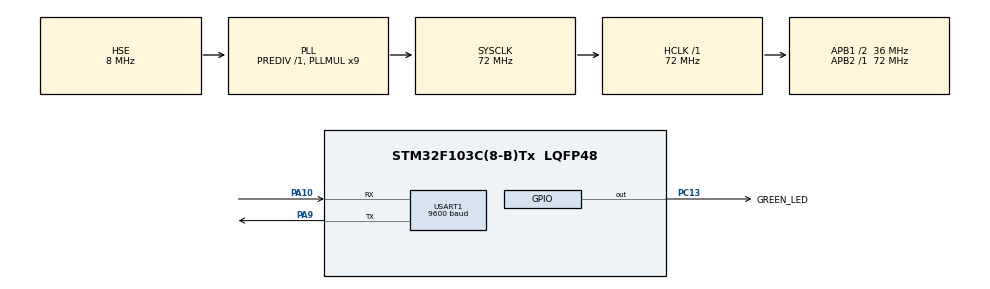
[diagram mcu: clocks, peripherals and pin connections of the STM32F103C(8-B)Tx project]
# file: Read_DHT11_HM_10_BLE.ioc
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Mcu.Family=STM32F1
Mcu.Name=STM32F103C(8-B)Tx
Mcu.Package=LQFP48
NVIC.PriorityGroup=NVIC_PRIORITYGROUP_4
NVIC.USART1_IRQn=true\:0\:0\:false\:false\:true\:true\:true
PA10.Mode=Asynchronous
PA10.Signal=USART1_RX
PA13.Mode=Serial_Wire
PA13.Signal=SYS_JTMS-SWDIO
PA14.Mode=Serial_Wire
PA14.Signal=SYS_JTCK-SWCLK
PA9.Mode=Asynchronous
PA9.Signal=USART1_TX
PC13-TAMPER-RTC.GPIO_Label=GREEN_LED
PC13-TAMPER-RTC.Signal=GPIO_Output
PD0-OSC_IN.Mode=HSE-External-Oscillator
PD0-OSC_IN.Signal=RCC_OSC_IN
PD1-OSC_OUT.Mode=HSE-External-Oscillator
PD1-OSC_OUT.Signal=RCC_OSC_OUT
ProjectManager.HeapSize=0x200
ProjectManager.StackSize=0x400
ProjectManager.TargetToolchain=STM32CubeIDE
RCC.AHBFreq_Value=72000000
RCC.APB1CLKDivider=RCC_HCLK_DIV2
RCC.APB1Freq_Value=36000000
RCC.APB1TimFreq_Value=72000000
RCC.APB2Freq_Value=72000000
RCC.APB2TimFreq_Value=72000000
RCC.HCLKFreq_Value=72000000
RCC.PLLMUL=RCC_PLL_MUL9
RCC.PLLSourceVirtual=RCC_PLLSOURCE_HSE
RCC.SYSCLKFreq_VALUE=72000000
RCC.SYSCLKSource=RCC_SYSCLKSOURCE_PLLCLK
RCC.USBFreq_Value=72000000
TIM1.Prescaler=71
USART1.BaudRate=9600
USART1.VirtualMode=VM_ASYNC
VP_TIM1_VS_ClockSourceINT.Mode=Internal
board=custom

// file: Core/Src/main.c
/* USER CODE BEGIN Header */
/**
  ******************************************************************************
  * @file           : main.c
  * @brief          : Main program body
  ******************************************************************************
  * @attention
  *
  * <h2><center>&copy; Copyright (c) 2025 STMicroelectronics.
  * All rights reserved.</center></h2>
  *
  * This software component is licensed by ST under BSD 3-Clause license,
  * the "License"; You may not use this file except in compliance with the
  * License. You may obtain a copy of the License at:
  *                        opensource.org/licenses/BSD-3-Clause
  *
  ******************************************************************************
  */
/* USER CODE END Header */
#include "main.h"

/* USER CODE BEGIN Includes */
#include "stdio.h"
#include "string.h"
/* USER CODE END Includes */

/* USER CODE BEGIN PD */
#define DHT11_PORT GPIOA
#define DHT11_PIN GPIO_PIN_0

#define HM10_UART &huart1  // Define the UART used for HM-10
/* USER CODE END PD */

TIM_HandleTypeDef htim1;

UART_HandleTypeDef huart1;

/* USER CODE BEGIN PV */
uint8_t dht11_data[5];
char uart_buffer[127];
/* USER CODE END PV */

void SystemClock_Config(void);
static void MX_GPIO_Init(void);
static void MX_USART1_UART_Init(void);
static void MX_TIM1_Init(void);

/* USER CODE BEGIN 0 */

void microDelay (uint16_t delay)
{
  __HAL_TIM_SET_COUNTER(&htim1, 0);
  while (__HAL_TIM_GET_COUNTER(&htim1) < delay);
}

/* Function to initialize communication with DHT11 */
void DHT11_Start(void)
{
  GPIO_InitTypeDef GPIO_InitStruct = {0};

  /* Configure pin as output */
  GPIO_InitStruct.Pin = DHT11_PIN;
  GPIO_InitStruct.Mode = GPIO_MODE_OUTPUT_PP;
  GPIO_InitStruct.Pull = GPIO_NOPULL;
  GPIO_InitStruct.Speed = GPIO_SPEED_FREQ_LOW;
  HAL_GPIO_Init(DHT11_PORT, &GPIO_InitStruct);

  HAL_GPIO_WritePin(DHT11_PORT, DHT11_PIN, GPIO_PIN_RESET);
  HAL_Delay(20); // Pull low for >18ms
  HAL_GPIO_WritePin(DHT11_PORT, DHT11_PIN, GPIO_PIN_SET);
  microDelay(30); // Pull high for 30us

  /* Configure pin as input */
  GPIO_InitStruct.Mode = GPIO_MODE_INPUT;
  GPIO_InitStruct.Pull = GPIO_NOPULL;
  HAL_GPIO_Init(DHT11_PORT, &GPIO_InitStruct);
}

uint8_t DHT11_Check_Response(void)
{
  uint8_t response = 0;
  microDelay(40);

  if (!HAL_GPIO_ReadPin(DHT11_PORT, DHT11_PIN))
  {
	  microDelay(80);
    if (HAL_GPIO_ReadPin(DHT11_PORT, DHT11_PIN))
      response = 1;
  }
  while (HAL_GPIO_ReadPin(DHT11_PORT, DHT11_PIN)); // wait for the pin to go low

  return response;
}

uint8_t DHT11_Read(void)
{
  uint8_t i, j;
  for (j = 0; j < 8; j++)
  {
    while (!HAL_GPIO_ReadPin(DHT11_PORT, DHT11_PIN)); // Wait for pin to go high
    microDelay(40); // 40us delay
    if (!HAL_GPIO_ReadPin(DHT11_PORT, DHT11_PIN))
    {
      i &= ~(1 << (7 - j)); // Write 0
    }
    else
    {
      i |= (1 << (7 - j)); // Write 1
    }
    while (HAL_GPIO_ReadPin(DHT11_PORT, DHT11_PIN)); // Wait for pin to go low
  }
  return i;
}

void HM10_SendCommand(const char *command) {
    HAL_UART_Transmit(HM10_UART, (uint8_t *)command, strlen(command), HAL_MAX_DELAY);
    HAL_UART_Transmit(HM10_UART, (uint8_t *)"\r\n", 2, HAL_MAX_DELAY);
}

void HM10_Init(void) {
    // Send AT commands to configure the HM-10 module
    HM10_SendCommand("AT");                 // Check if the module responds
    HAL_Delay(100);
    HM10_SendCommand("AT+NAMEHM10_Module"); // Set the BLE name
    HAL_Delay(100);
    HM10_SendCommand("AT+ROLE0");           // Set role as Peripheral
    HAL_Delay(100);
    HM10_SendCommand("AT+RESET");           // Reset to apply changes
    HAL_Delay(1000);
}

void BLE_TransmitData(const char *data) {
    HAL_UART_Transmit(HM10_UART, (uint8_t *)data, strlen(data), HAL_MAX_DELAY);
}

//void BLE_ReceiveData(void) {
//    if (HAL_UART_Receive(HM10_UART, (uint8_t *)hm10_rx_buffer, HM10_BUFFER_SIZE, 1000) == HAL_OK) {
//        printf("Received via BLE: %s\r\n", hm10_rx_buffer);
//    }
//}

/* USER CODE END 0 */

int main(void)
{

  /* MCU Configuration--------------------------------------------------------*/

  /* Reset of all peripherals, Initializes the Flash interface and the Systick. */
  HAL_Init();

  /* Configure the system clock */
  SystemClock_Config();

  /* Initialize all configured peripherals */
  MX_GPIO_Init();
  MX_USART1_UART_Init();
  MX_TIM1_Init();
  /* USER CODE BEGIN 2 */
  HAL_TIM_Base_Start(&htim1); // Start timer for microsecond delays

  // Initialize HM-10 BLE module
  //HM10_Init();

  //int counter = 0;
  /* USER CODE END 2 */

  /* Infinite loop */
  /* USER CODE BEGIN WHILE */
  while (1)
  {
	//printf("Debug: Counter = %d\r\n", counter++);
	//HAL_GPIO_TogglePin(GPIOC, GPIO_PIN_13);
    /* Start DHT11 communication */
    DHT11_Start();
    if (DHT11_Check_Response())
    {
      dht11_data[0] = DHT11_Read(); // Humidity integer
      dht11_data[1] = DHT11_Read(); // Humidity decimal
      dht11_data[2] = DHT11_Read(); // Temperature integer
      dht11_data[3] = DHT11_Read(); // Temperature decimal
      dht11_data[4] = DHT11_Read(); // Checksum

//      if (1 < dht11_data[2] && dht11_data[2] < 95) {
//      	HAL_GPIO_TogglePin(GPIOC, GPIO_PIN_13);
//      }

      if ((dht11_data[0] + dht11_data[1] + dht11_data[2] + dht11_data[3]) == dht11_data[4])
      {
        /* Format the data */
        sprintf(uart_buffer, "Temp: %d.%dC, Humidity: %d.%d%%\r\n",
                dht11_data[2], dht11_data[3], dht11_data[0], dht11_data[1]);

        /* Send data via UART to HM10 */
        //HAL_UART_Transmit(&huart1, (uint8_t *)uart_buffer, strlen(uart_buffer), 100);
        BLE_TransmitData(uart_buffer);

        HAL_GPIO_TogglePin(GPIOC, GPIO_PIN_13);
      }
    }

    HAL_Delay(2000); // Wait for 2 seconds before the next reading
    /* USER CODE END WHILE */

  }
}

void SystemClock_Config(void)
{
  RCC_OscInitTypeDef RCC_OscInitStruct = {0};
  RCC_ClkInitTypeDef RCC_ClkInitStruct = {0};

  /** Initializes the RCC Oscillators according to the specified parameters
  * in the RCC_OscInitTypeDef structure.
  */
  RCC_OscInitStruct.OscillatorType = RCC_OSCILLATORTYPE_HSE;
  RCC_OscInitStruct.HSEState = RCC_HSE_ON;
  RCC_OscInitStruct.HSEPredivValue = RCC_HSE_PREDIV_DIV1;
  RCC_OscInitStruct.HSIState = RCC_HSI_ON;
  RCC_OscInitStruct.PLL.PLLState = RCC_PLL_ON;
  RCC_OscInitStruct.PLL.PLLSource = RCC_PLLSOURCE_HSE;
  RCC_OscInitStruct.PLL.PLLMUL = RCC_PLL_MUL9;
  if (HAL_RCC_OscConfig(&RCC_OscInitStruct) != HAL_OK)
  {
    Error_Handler();
  }
  /** Initializes the CPU, AHB and APB buses clocks
  */
  RCC_ClkInitStruct.ClockType = RCC_CLOCKTYPE_HCLK|RCC_CLOCKTYPE_SYSCLK
                              |RCC_CLOCKTYPE_PCLK1|RCC_CLOCKTYPE_PCLK2;
  RCC_ClkInitStruct.SYSCLKSource = RCC_SYSCLKSOURCE_PLLCLK;
  RCC_ClkInitStruct.AHBCLKDivider = RCC_SYSCLK_DIV1;
  RCC_ClkInitStruct.APB1CLKDivider = RCC_HCLK_DIV2;
  RCC_ClkInitStruct.APB2CLKDivider = RCC_HCLK_DIV1;

  if (HAL_RCC_ClockConfig(&RCC_ClkInitStruct, FLASH_LATENCY_2) != HAL_OK)
  {
    Error_Handler();
  }
}

static void MX_TIM1_Init(void)
{

  TIM_ClockConfigTypeDef sClockSourceConfig = {0};
  TIM_MasterConfigTypeDef sMasterConfig = {0};

  htim1.Instance = TIM1;
  htim1.Init.Prescaler = 71;
  htim1.Init.CounterMode = TIM_COUNTERMODE_UP;
  htim1.Init.Period = 65535;
  htim1.Init.ClockDivision = TIM_CLOCKDIVISION_DIV1;
  htim1.Init.RepetitionCounter = 0;
  htim1.Init.AutoReloadPreload = TIM_AUTORELOAD_PRELOAD_DISABLE;
  if (HAL_TIM_Base_Init(&htim1) != HAL_OK)
  {
    Error_Handler();
  }
  sClockSourceConfig.ClockSource = TIM_CLOCKSOURCE_INTERNAL;
  if (HAL_TIM_ConfigClockSource(&htim1, &sClockSourceConfig) != HAL_OK)
  {
    Error_Handler();
  }
  sMasterConfig.MasterOutputTrigger = TIM_TRGO_RESET;
  sMasterConfig.MasterSlaveMode = TIM_MASTERSLAVEMODE_DISABLE;
  if (HAL_TIMEx_MasterConfigSynchronization(&htim1, &sMasterConfig) != HAL_OK)
  {
    Error_Handler();
  }

}

static void MX_USART1_UART_Init(void)
{

  huart1.Instance = USART1;
  huart1.Init.BaudRate = 9600;
  huart1.Init.WordLength = UART_WORDLENGTH_8B;
  huart1.Init.StopBits = UART_STOPBITS_1;
  huart1.Init.Parity = UART_PARITY_NONE;
  huart1.Init.Mode = UART_MODE_TX_RX;
  huart1.Init.HwFlowCtl = UART_HWCONTROL_NONE;
  huart1.Init.OverSampling = UART_OVERSAMPLING_16;
  if (HAL_UART_Init(&huart1) != HAL_OK)
  {
    Error_Handler();
  }

}

static void MX_GPIO_Init(void)
{
  GPIO_InitTypeDef GPIO_InitStruct = {0};

  /* GPIO Ports Clock Enable */
  __HAL_RCC_GPIOC_CLK_ENABLE();
  __HAL_RCC_GPIOD_CLK_ENABLE();
  __HAL_RCC_GPIOA_CLK_ENABLE();

  /*Configure GPIO pin Output Level */
  HAL_GPIO_WritePin(GREEN_LED_GPIO_Port, GREEN_LED_Pin, GPIO_PIN_RESET);

  /*Configure GPIO pin Output Level */
  HAL_GPIO_WritePin(GPIOA, GPIO_PIN_0, GPIO_PIN_RESET);

  /*Configure GPIO pin : GREEN_LED_Pin */
  GPIO_InitStruct.Pin = GREEN_LED_Pin;
  GPIO_InitStruct.Mode = GPIO_MODE_OUTPUT_PP;
  GPIO_InitStruct.Pull = GPIO_NOPULL;
  GPIO_InitStruct.Speed = GPIO_SPEED_FREQ_LOW;
  HAL_GPIO_Init(GREEN_LED_GPIO_Port, &GPIO_InitStruct);

  /*Configure GPIO pin : PA0 */
  GPIO_InitStruct.Pin = GPIO_PIN_0;
  GPIO_InitStruct.Mode = GPIO_MODE_OUTPUT_PP;
  GPIO_InitStruct.Pull = GPIO_NOPULL;
  GPIO_InitStruct.Speed = GPIO_SPEED_FREQ_LOW;
  HAL_GPIO_Init(GPIOA, &GPIO_InitStruct);

}

/* USER CODE BEGIN 4 */
int _write(int file, char *ptr, int len)
 {
	 int DataIdx;
	 for (DataIdx = 0; DataIdx < len; DataIdx++)
	 {
		 ITM_SendChar(*ptr++);
	 }
	 return len;
 }
/* USER CODE END 4 */

void Error_Handler(void)
{
  __disable_irq();
  while (1)
  {
  }
}

/************************ (C) COPYRIGHT STMicroelectronics *****END OF FILE****/
